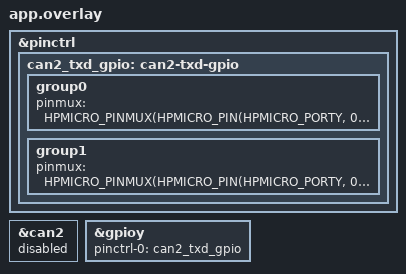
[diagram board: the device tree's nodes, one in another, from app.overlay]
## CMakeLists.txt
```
cmake_minimum_required(VERSION 3.20.0)

set(ZEPHYR_EXTRA_MODULES "D:/MCU/hpm/zephyr_sdk_glue")
set(HPM_SDK_DIR "D:/MCU/hpm/hpm_sdk" CACHE PATH "")
get_filename_component(HPM5361_BOARD_DIR "${CMAKE_CURRENT_LIST_DIR}/../.." ABSOLUTE)
set(BOARD_DIR "${HPM5361_BOARD_DIR}" CACHE PATH "" FORCE)
set(BOARD_DIRECTORIES "${HPM5361_BOARD_DIR}" CACHE INTERNAL "Board directories" FORCE)

find_package(Zephyr REQUIRED HINTS $ENV{ZEPHYR_BASE})
project(can2_txd_probe)

target_sources(app PRIVATE src/main.c)
```

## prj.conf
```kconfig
CONFIG_CONSOLE=n
CONFIG_UART_CONSOLE=n
CONFIG_BOOT_BANNER=n
CONFIG_ICACHE=n
CONFIG_DCACHE=n
```

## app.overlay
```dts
#include <dt-bindings/pinctrl/hpmicro-pinctrl-common.h>

&pinctrl {
	can2_txd_gpio: can2-txd-gpio {
		group0 {
			pinmux = <HPMICRO_PINMUX(HPMICRO_PIN(HPMICRO_PORTY, 0), IOC_TYPE_PIOC, 0, 3)>;
		};
		group1 {
			pinmux = <HPMICRO_PINMUX(HPMICRO_PIN(HPMICRO_PORTY, 0), IOC_TYPE_IOC, 0, 0)>;
		};
	};
};

&can2 {
	status = "disabled";
};

&gpioy {
	pinctrl-0 = <&can2_txd_gpio>;
	pinctrl-names = "default";
	status = "okay";
};
```

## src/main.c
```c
#include <zephyr/device.h>
#include <zephyr/devicetree.h>
#include <zephyr/drivers/gpio.h>
#include <zephyr/kernel.h>

#define CAN2_TXD_GPIO DEVICE_DT_GET(DT_NODELABEL(gpioy))
#define CAN2_TXD_PIN 0U

volatile unsigned int can2_txd_probe_cycles;
volatile int can2_txd_probe_error;

int main(void)
{
	const struct device *gpio = CAN2_TXD_GPIO;

	if (!device_is_ready(gpio)) {
		can2_txd_probe_error = -1;
		return -1;
	}

	can2_txd_probe_error = gpio_pin_configure(gpio, CAN2_TXD_PIN, GPIO_OUTPUT_HIGH);
	if (can2_txd_probe_error != 0) {
		return can2_txd_probe_error;
	}

	while (true) {
		gpio_pin_set(gpio, CAN2_TXD_PIN, 0);
		k_sleep(K_MSEC(500));
		gpio_pin_set(gpio, CAN2_TXD_PIN, 1);
		k_sleep(K_MSEC(500));
		++can2_txd_probe_cycles;
	}
}
```
